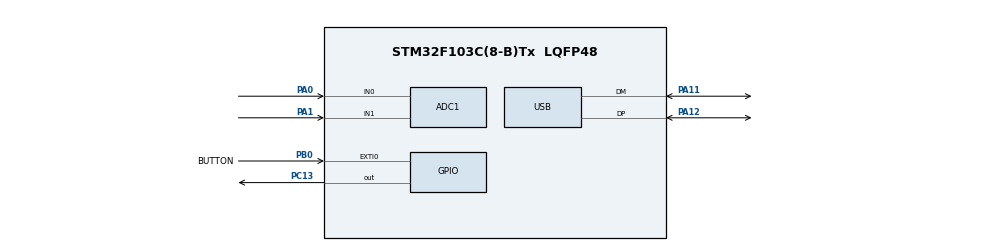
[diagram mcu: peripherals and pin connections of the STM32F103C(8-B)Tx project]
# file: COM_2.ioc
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ADC1.Channel-0\#ChannelRegularConversion=ADC_CHANNEL_0
ADC1.Channel-1\#ChannelRegularConversion=ADC_CHANNEL_1
ADC1.DataAlign=ADC_DATAALIGN_RIGHT
ADC1.NbrOfConversion=2
ADC1.NbrOfConversionFlag=1
ADC1.Rank-0\#ChannelRegularConversion=1
ADC1.Rank-1\#ChannelRegularConversion=2
ADC1.SamplingTime-0\#ChannelRegularConversion=ADC_SAMPLETIME_7CYCLES_5
ADC1.SamplingTime-1\#ChannelRegularConversion=ADC_SAMPLETIME_7CYCLES_5
ADC1.master=1
Dma.ADC1.0.Direction=DMA_PERIPH_TO_MEMORY
Dma.ADC1.0.Instance=DMA1_Channel1
Dma.ADC1.0.MemDataAlignment=DMA_MDATAALIGN_HALFWORD
Dma.ADC1.0.MemInc=DMA_MINC_ENABLE
Dma.ADC1.0.Mode=DMA_NORMAL
Dma.ADC1.0.PeriphDataAlignment=DMA_PDATAALIGN_HALFWORD
Dma.ADC1.0.PeriphInc=DMA_PINC_DISABLE
Dma.ADC1.0.Priority=DMA_PRIORITY_HIGH
Dma.Request0=ADC1
Mcu.Family=STM32F1
Mcu.Name=STM32F103C(8-B)Tx
Mcu.Package=LQFP48
NVIC.DMA1_Channel1_IRQn=true\:2\:0\:true\:false\:true\:false\:true\:true
NVIC.EXTI0_IRQn=true\:3\:0\:true\:false\:true\:true\:true\:true
NVIC.PriorityGroup=NVIC_PRIORITYGROUP_4
NVIC.TIM2_IRQn=true\:1\:0\:true\:false\:true\:true\:true\:true
NVIC.USB_LP_CAN1_RX0_IRQn=true\:0\:0\:false\:false\:true\:false\:true\:true
PA0-WKUP.Signal=ADCx_IN0
PA1.Signal=ADCx_IN1
PA11.Mode=Device
PA11.Signal=USB_DM
PA12.Mode=Device
PA12.Signal=USB_DP
PA13.Mode=Serial_Wire
PA13.Signal=SYS_JTMS-SWDIO
PA14.Mode=Serial_Wire
PA14.Signal=SYS_JTCK-SWCLK
PB0.GPIO_Label=BUTTON
PB0.GPIO_ModeDefaultEXTI=GPIO_MODE_IT_RISING_FALLING
PB0.GPIO_PuPd=GPIO_PULLDOWN
PB0.Signal=GPXTI0
PC13-TAMPER-RTC.GPIO_PuPd=GPIO_NOPULL
PC13-TAMPER-RTC.PinState=GPIO_PIN_SET
PC13-TAMPER-RTC.Signal=GPIO_Output
PD0-OSC_IN.Mode=HSE-External-Oscillator
PD0-OSC_IN.Signal=RCC_OSC_IN
PD1-OSC_OUT.Mode=HSE-External-Oscillator
PD1-OSC_OUT.Signal=RCC_OSC_OUT
ProjectManager.HeapSize=0x200
ProjectManager.StackSize=0x400
ProjectManager.TargetToolchain=STM32CubeIDE
RCC.ADCPresc=RCC_ADCPCLK2_DIV8
RCC.AHBCLKDivider=RCC_SYSCLK_DIV4
RCC.AHBFreq_Value=12000000
RCC.APB1Freq_Value=12000000
RCC.APB1TimFreq_Value=12000000
RCC.APB2Freq_Value=12000000
RCC.APB2TimFreq_Value=12000000
RCC.HCLKFreq_Value=12000000
RCC.PLLMUL=RCC_PLL_MUL6
RCC.SYSCLKFreq_VALUE=48000000
RCC.SYSCLKSource=RCC_SYSCLKSOURCE_PLLCLK
RCC.USBFreq_Value=48000000
SH.ADCx_IN0.0=ADC1_IN0,IN0
SH.ADCx_IN1.0=ADC1_IN1,IN1
TIM2.Period=499
TIM2.Prescaler=11999
USB_DEVICE.CLASS_NAME_FS=CDC
USB_DEVICE.VirtualMode=Cdc
USB_DEVICE.VirtualModeFS=Cdc_FS
VP_TIM2_VS_ClockSourceINT.Mode=Internal
VP_USB_DEVICE_VS_USB_DEVICE_CDC_FS.Mode=CDC_FS
board=custom

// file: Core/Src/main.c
/* USER CODE BEGIN Header */
/**
  ******************************************************************************
  * @file           : main.c
  * @brief          : Main program body
  ******************************************************************************
  * @attention
  *
  * Copyright (c) 2022 STMicroelectronics.
  * All rights reserved.
  *
  * This software is licensed under terms that can be found in the LICENSE file
  * in the root directory of this software component.
  * If no LICENSE file comes with this software, it is provided AS-IS.
  *
  ******************************************************************************
  */
/* USER CODE END Header */
#include "main.h"
#include "usb_device.h"

/* USER CODE BEGIN Includes */
#include "../LogicH/CircBuff.h"
#include "../LogicH/CircBuff.h"

#include "InitPeriphery.h"
#include "Func.h"
#include "Stack.h"
//#include "CircBuff.h"
/* USER CODE END Includes */

/* USER CODE BEGIN PD */
#define max(x, y) ( (x) > (y) ? (x) : (y) )
#define min(x, y) ( (x) < (y) ? (x) : (y) )
/* USER CODE END PD */

ADC_HandleTypeDef hadc1;
DMA_HandleTypeDef hdma_adc1;
TIM_HandleTypeDef htim2;

/* USER CODE BEGIN PV */

// char str_V[23] = {0};

//  char trans_str[64] = {0,};

 // volatile uint16_t adc_2[2] = {0,}; // у нас два канала поэтому массив из двух элементов

 // char str[16];

 // volatile uint8_t flag = 0;

  // volatile uint8_t FlagInterADC = 0;
  // volatile uint8_t	FlagStartADC =0;

  // uint16_t adc_buf[20];

 // int btn_cnt =0;

//  uint8_t Rec_Data[4]={0};   // 8
//  uint32_t Rec_Len=0;

  //uint32_t Sum_Len=0;

//  short Ovf=0;

//  uint32_t Rec_Stack[16]={0};  // 32 64

// int ReceiveFlag = 0;

// int OutRead = 0;

//const char first[11] = __DATE__;
//const char second[8] = __TIME__;
 	   // char *third =  __DATE__  __TIME__;

 	// int xx =  sprintf (str_temp, "\r\n %s %s", __DATE__ , __TIME__);

// extern uint8_t CDC_Transmit_FS(uint8_t* Buf, uint16_t Len);
/* USER CODE END PV */

//void SystemClock_Config(void);
//static void MX_GPIO_Init(void);
//static void MX_DMA_Init(void);
//static void MX_ADC1_Init(void);
//static void MX_TIM2_Init(void);
/* USER CODE BEGIN PFP */

// void IfReceivedA(void);
//void IfReceivedL(void);

//void ADC_Result(void);

// void StartMenu(void);

// void ADCstop(void);
// void ADC_Start(void);

//extern uint8_t BusyCheck (void);
//extern uint8_t CDC_Transmit_FS(uint8_t* Buf, uint16_t Len);

//extern uint8_t  USBD_CDC_EP0_RxReady(USBD_HandleTypeDef *pdev);

// void ReceiveHandler(void);

// void StackHandler(uint8_t* Data, uint32_t Len);

// int OutputHandler(void);

// void OutputStack(char TransMes[], uint8_t Len);
//uint8_t CDC_Transmit_FS(uint8_t* Buf, uint16_t Len);

/* USER CODE END PFP */

/* USER CODE BEGIN 0 */

// extern struct queue queueIn, queueOut;

/* USER CODE END 0 */

int main(void)
{
  /* USER CODE BEGIN 1 */

		BuffInit();

	//put(&queue, "hello ", 6);
	//put(&queue, "world\n", 7);

//	char s[13];

	//get(&queue, (uint8_t *) s, 13);

  /* USER CODE END 1 */

  /* MCU Configuration--------------------------------------------------------*/

  /* Reset of all peripherals, Initializes the Flash interface and the Systick. */
  HAL_Init();

  /* Configure the system clock */
  SystemClock_Config();

  /* Initialize all configured peripherals */
  MX_GPIO_Init();
  MX_USB_DEVICE_Init();
  MX_DMA_Init();
  MX_ADC1_Init();  /// пересмотреть без передачи
  MX_TIM2_Init();
  /* USER CODE BEGIN 2 */

 // StartMenu();

  /* USER CODE END 2 */

  /* Infinite loop */
  /* USER CODE BEGIN WHILE */
  //StartMenu();

 // StartMenu();

 // OutputStack( Start_Menu_1,sizeof(Start_Menu_1) );  // first line is not displayed

  while (1)
  {
    /* USER CODE END WHILE */

    /* USER CODE BEGIN 3 */
	//  if(ReceiveFlag == 1){

			 // StackHandler();
		//	  ReceiveFlag = 0;
		//  }

		//  if(BusyFlag == USBD_OK && Sum_Len!=i ){

	      LogicReadInpStack();

	     // if(BusyFlag == USBD_OK && queueOut.bytes_avail!=0 ){

	      LogicOutpStackCheck();

	      }

  }

  /* USER CODE END 3 */

void Error_Handler(void)
{
  __disable_irq();
  while (1)
  {
  }
}
